# CC1312PSIP register map
File version: 1.0
CPU: CM4 1.0, other endian, MPU, FPU, 3 interrupt priority bits
Registers are 32-bit, read-write, reset 0x0 unless marked. A register's access mark holds for its fields unless they carry their own. Offsets are from the block's base; [hi:lo] are bit positions; 'fields as' and 'values as' point back to an identical list.

## VIMS — Versatile Instruction Memory System Controls memory access to the Flash and encapsulates the following instruction memories: - Boot ROM - Cache / GPRAM
Base 0x40034000
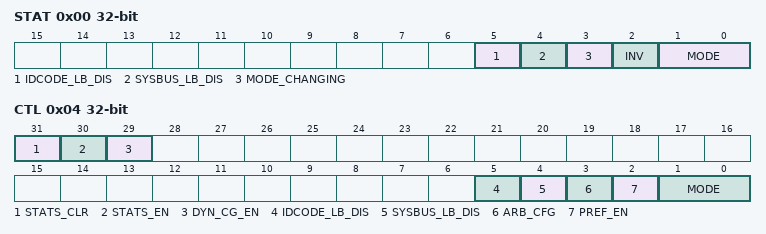
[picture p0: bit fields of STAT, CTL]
0x00 STAT — Status Displays current VIMS mode and line buffer status
  [5] IDCODE_LB_DIS ro — [5:5] Icode/Dcode flash line buffer status 0: Enabled or in transition to disabled 1: Disabled and flushed
  [4] SYSBUS_LB_DIS ro — [4:4] Sysbus flash line buffer control 0: Enabled or in transition to disabled 1: Disabled and flushed
  [3] MODE_CHANGING ro — [3:3] VIMS mode change status 0: VIMS is in the mode defined by MODE 1: VIMS is in the process of changing to the mode given in CTL.MODE
  [2] INV ro — [2:2] This bit is set when invalidation of the cache memory is active / ongoing
  [1:0] MODE ro — [1:0] Current VIMS mode
    3=OFF (VIMS Off mode); 1=CACHE (VIMS Cache mode); 0=GPRAM (VIMS GPRAM mode)
0x04 CTL — Control Configure VIMS mode and line buffer settings
  [31] STATS_CLR — [31:31] Set this bit to clear statistic counters.
  [30] STATS_EN — [30:30] Set this bit to enable statistic counters.
  [29] DYN_CG_EN — [29:29] 0: The in-built clock gate functionality is bypassed. 1: The in-built clock gate functionality is enabled, automatically gating the clock when not needed.
  [5] IDCODE_LB_DIS — [5:5] Icode/Dcode flash line buffer control 0: Enable 1: Disable
  [4] SYSBUS_LB_DIS — [4:4] Sysbus flash line buffer control 0: Enable 1: Disable
  [3] ARB_CFG — [3:3] Icode/Dcode and sysbus arbitation scheme 0: Static arbitration (icode/docde > sysbus) 1: Round-robin arbitration
  [2] PREF_EN — [2:2] Tag prefetch control 0: Disabled 1: Enabled
  [1:0] MODE — [1:0] VIMS mode request. Write accesses to this field will be blocked while STAT.MODE_CHANGING is set to 1.
    values as STAT.MODE

## WDT — Watchdog Timer
Base 0x40080000
0x00 LOAD reset 0xFFFFFFFF — Configuration
  [31:0] WDTLOAD — [31:0] This register is the 32-bit interval value used by the 32-bit counter. When this register is written, the value is immediately loaded and the counter is restarted to count down from the new value. If this register is loaded with 0x0000.0000, an interrupt is immediately generated.
0x04 VALUE reset 0xFFFFFFFF — Current Count Value
  [31:0] WDTVALUE ro — [31:0] This register contains the current count value of the timer.
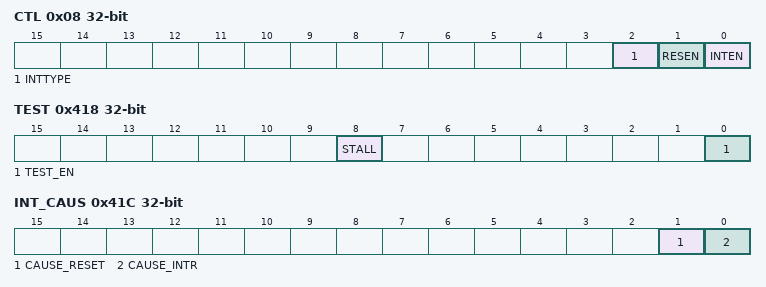
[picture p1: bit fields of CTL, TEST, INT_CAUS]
0x08 CTL — Control
  [2] INTTYPE — [2:2] WDT Interrupt Type 0: WDT interrupt is a standard interrupt. 1: WDT interrupt is a non-maskable interrupt.
    1=NONMASKABLE (Non-maskable interrupt); 0=MASKABLE (Maskable interrupt)
  [1] RESEN — [1:1] WDT Reset Enable. Defines the function of the WDT reset source (see PRCM:WARMRESET.WDT_STAT if enabled) 0: Disabled. 1: Enable the Watchdog reset output.
    1=EN (Reset output Enabled); 0=DIS (Reset output Disabled)
  [0] INTEN — [0:0] WDT Interrupt Enable 0: Interrupt event disabled. 1: Interrupt event enabled. Once set, this bit can only be cleared by a hardware reset.
    1=EN (Interrupt Enabled); 0=DIS (Interrupt Disabled)
0x0C ICR — Interrupt Clear
  [31:0] WDTICR wo — [31:0] This register is the interrupt clear register. A write of any value to this register clears the WDT interrupt and reloads the 32-bit counter from the LOAD register.
0x10 RIS — Raw Interrupt Status
  [0] WDTRIS ro — [0:0] This register is the raw interrupt status register. WDT interrupt events can be monitored via this register if the controller interrupt is masked. Value Description 0: The WDT has not timed out 1: A WDT time-out event has occurred
0x14 MIS — Masked Interrupt Status
  [0] WDTMIS ro — [0:0] This register is the masked interrupt status register. The value of this register is the logical AND of the raw interrupt bit and the WDT interrupt enable bit CTL.INTEN. Value Description 0: The WDT has not timed out or is masked. 1: An unmasked WDT time-out event has occurred.
0x418 TEST — Test Mode
  [8] STALL — [8:8] WDT Stall Enable 0: The WDT timer continues counting if the CPU is stopped with a debugger. 1: If the CPU is stopped with a debugger, the WDT stops counting. Once the CPU is restarted, the WDT resumes counting.
    1=EN (Enable STALL); 0=DIS (Disable STALL)
  [0] TEST_EN — [0:0] The test enable bit 0: Enable external reset 1: Disables the generation of an external reset. Instead bit 1 of the INT_CAUS register is set and an interrupt is generated
    1=EN (Test mode Enabled); 0=DIS (Test mode Disabled)
0x41C INT_CAUS — Interrupt Cause Test Mode
  [1] CAUSE_RESET ro — [1:1] Indicates that the cause of an interrupt was a reset generated but blocked due to TEST.TEST_EN (only possible when TEST.TEST_EN is set).
  [0] CAUSE_INTR ro — [0:0] Replica of RIS.WDTRIS
0xC00 LOCK
  [31:0] WDTLOCK — [31:0] WDT Lock: A write of the value 0x1ACC.E551 unlocks the watchdog registers for write access. A write of any other value reapplies the lock, preventing any register updates (NOTE: TEST.TEST_EN bit is not lockable). A read of this register returns the following values: 0x0000.0000: Unlocked 0x0000.0001: Locked
